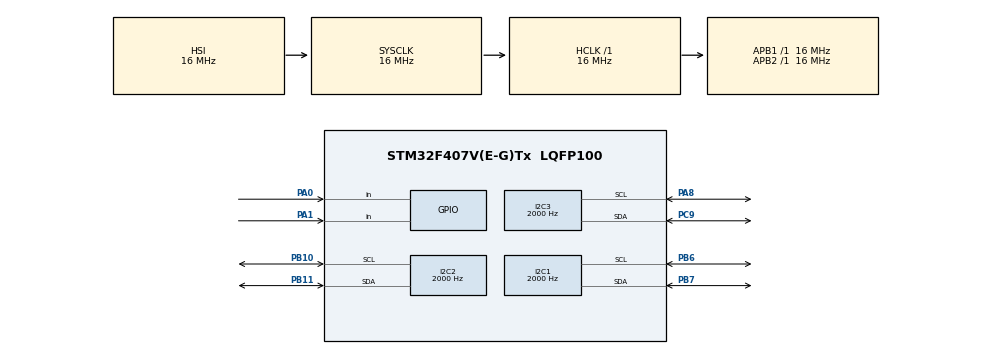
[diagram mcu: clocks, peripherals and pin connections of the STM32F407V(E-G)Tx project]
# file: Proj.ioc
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I2C1.ClockSpeed=2000
I2C1.OwnAddress=51
I2C2.ClockSpeed=2000
I2C2.OwnAddress=52
I2C3.ClockSpeed=2000
I2C3.OwnAddress=53
Mcu.Family=STM32F4
Mcu.Name=STM32F407V(E-G)Tx
Mcu.Package=LQFP100
NVIC.I2C1_ER_IRQn=true\:0\:0\:false\:false\:true\:true\:true
NVIC.I2C1_EV_IRQn=true\:0\:0\:false\:false\:true\:true\:true
NVIC.PriorityGroup=NVIC_PRIORITYGROUP_4
PA0-WKUP.Signal=GPIO_Input
PA1.Signal=GPIO_Input
PA8.Mode=I2C
PA8.Signal=I2C3_SCL
PB10.Mode=I2C
PB10.Signal=I2C2_SCL
PB11.Mode=I2C
PB11.Signal=I2C2_SDA
PB6.Mode=I2C
PB6.Signal=I2C1_SCL
PB7.Mode=I2C
PB7.Signal=I2C1_SDA
PC9.Mode=I2C
PC9.Signal=I2C3_SDA
ProjectManager.HeapSize=0x200
ProjectManager.StackSize=0x400
ProjectManager.TargetToolchain=TrueSTUDIO
RCC.AHBFreq_Value=16000000
RCC.APB1Freq_Value=16000000
RCC.APB2Freq_Value=16000000
RCC.CortexFreq_Value=16000000
RCC.HSE_VALUE=25000000
RCC.HSI_VALUE=16000000
RCC.LSE_VALUE=32768
RCC.SYSCLKFreq_VALUE=16000000
RCC.VCOOutputFreq_Value=192000000
board=custom

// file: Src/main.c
/* USER CODE BEGIN Header */
/**
  ******************************************************************************
  * @file           : main.c
  * @brief          : Main program body
  ******************************************************************************
  * @attention
  *
  * <h2><center>&copy; Copyright (c) 2020 STMicroelectronics.
  * All rights reserved.</center></h2>
  *
  * This software component is licensed by ST under BSD 3-Clause license,
  * the "License"; You may not use this file except in compliance with the
  * License. You may obtain a copy of the License at:
  *                        opensource.org/licenses/BSD-3-Clause
  *
  ******************************************************************************
  */
/* USER CODE END Header */

#include "main.h"

/* USER CODE BEGIN Includes */
#include "I2CTests.h"
/* USER CODE END Includes */

void SystemClock_Config(void);
static void MX_GPIO_Init(void);
static void MX_I2C1_Init(void);
static void MX_I2C2_Init(void);
static void MX_I2C3_Init(void);

int main(void)
{

  /* MCU Configuration--------------------------------------------------------*/

  /* Reset of all peripherals, Initializes the Flash interface and the Systick. */
  HAL_Init();

  /* Configure the system clock */
  SystemClock_Config();

  /* Initialize all configured peripherals */
  MX_GPIO_Init();
  MX_I2C1_Init();
  MX_I2C2_Init();
  MX_I2C3_Init();

  /* Infinite loop */
  /* USER CODE BEGIN WHILE */
  uint8_t aTxBuffer[8] = {0x22, 0x22, 0x22};////�����, ���, ����
//  uint8_t adrDev = 0xD0;
  while (1)
  {
//	if(HAL_GPIO_ReadPin(GPIOA,GPIO_PIN_0) == GPIO_PIN_SET)
//	{
//		if(HAL_I2C_Slave_Receive(&hi2c1, aTxBuffer, (uint16_t)2, (uint32_t)2000) == HAL_OK)
//		{
//			asm("nop");
//		}
//	}
//
//	uint8_t res = HAL_GPIO_ReadPin(GPIOA,GPIO_PIN_1);
//	if(res == GPIO_PIN_SET)
//	{
//		HAL_I2C_DeInit(&hi2c1);
//		HAL_I2C_Init(&hi2c1);
//	}
//	while(HAL_I2C_Slave_Receive(&hi2c1, aTxBuffer, (uint16_t)1, (uint32_t)100) != HAL_OK);
    /* USER CODE END WHILE */

  }
}

void SystemClock_Config(void)
{
  RCC_OscInitTypeDef RCC_OscInitStruct = {0};
  RCC_ClkInitTypeDef RCC_ClkInitStruct = {0};

  /** Configure the main internal regulator output voltage
  */
  __HAL_RCC_PWR_CLK_ENABLE();
  __HAL_PWR_VOLTAGESCALING_CONFIG(PWR_REGULATOR_VOLTAGE_SCALE1);
  /** Initializes the CPU, AHB and APB busses clocks
  */
  RCC_OscInitStruct.OscillatorType = RCC_OSCILLATORTYPE_HSI;
  RCC_OscInitStruct.HSIState = RCC_HSI_ON;
  RCC_OscInitStruct.HSICalibrationValue = RCC_HSICALIBRATION_DEFAULT;
  RCC_OscInitStruct.PLL.PLLState = RCC_PLL_NONE;
  if (HAL_RCC_OscConfig(&RCC_OscInitStruct) != HAL_OK)
  {
    Error_Handler();
  }
  /** Initializes the CPU, AHB and APB busses clocks
  */
  RCC_ClkInitStruct.ClockType = RCC_CLOCKTYPE_HCLK|RCC_CLOCKTYPE_SYSCLK
                              |RCC_CLOCKTYPE_PCLK1|RCC_CLOCKTYPE_PCLK2;
  RCC_ClkInitStruct.SYSCLKSource = RCC_SYSCLKSOURCE_HSI;
  RCC_ClkInitStruct.AHBCLKDivider = RCC_SYSCLK_DIV1;
  RCC_ClkInitStruct.APB1CLKDivider = RCC_HCLK_DIV1;
  RCC_ClkInitStruct.APB2CLKDivider = RCC_HCLK_DIV1;

  if (HAL_RCC_ClockConfig(&RCC_ClkInitStruct, FLASH_LATENCY_0) != HAL_OK)
  {
    Error_Handler();
  }
}

static void MX_I2C1_Init(void)
{

  LL_I2C_InitTypeDef I2C_InitStruct = {0};

  LL_GPIO_InitTypeDef GPIO_InitStruct = {0};

  LL_AHB1_GRP1_EnableClock(LL_AHB1_GRP1_PERIPH_GPIOB);
  /**I2C1 GPIO Configuration
  PB6   ------> I2C1_SCL
  PB7   ------> I2C1_SDA
  */
  GPIO_InitStruct.Pin = LL_GPIO_PIN_6|LL_GPIO_PIN_7;
  GPIO_InitStruct.Mode = LL_GPIO_MODE_ALTERNATE;
  GPIO_InitStruct.Speed = LL_GPIO_SPEED_FREQ_VERY_HIGH;
  GPIO_InitStruct.OutputType = LL_GPIO_OUTPUT_OPENDRAIN;
  GPIO_InitStruct.Pull = LL_GPIO_PULL_UP;
  GPIO_InitStruct.Alternate = LL_GPIO_AF_4;
  LL_GPIO_Init(GPIOB, &GPIO_InitStruct);

  /* Peripheral clock enable */
  LL_APB1_GRP1_EnableClock(LL_APB1_GRP1_PERIPH_I2C1);

  /* I2C1 interrupt Init */
  NVIC_SetPriority(I2C1_EV_IRQn, NVIC_EncodePriority(NVIC_GetPriorityGrouping(),0, 0));
  NVIC_EnableIRQ(I2C1_EV_IRQn);
  NVIC_SetPriority(I2C1_ER_IRQn, NVIC_EncodePriority(NVIC_GetPriorityGrouping(),0, 0));
  NVIC_EnableIRQ(I2C1_ER_IRQn);

  /** I2C Initialization
  */
  LL_I2C_DisableOwnAddress2(I2C1);
  LL_I2C_DisableGeneralCall(I2C1);
  LL_I2C_EnableClockStretching(I2C1);
  I2C_InitStruct.PeripheralMode = LL_I2C_MODE_I2C;
  I2C_InitStruct.ClockSpeed = 2000;
  I2C_InitStruct.DutyCycle = LL_I2C_DUTYCYCLE_2;
  I2C_InitStruct.OwnAddress1 = 102;
  I2C_InitStruct.TypeAcknowledge = LL_I2C_ACK;
  I2C_InitStruct.OwnAddrSize = LL_I2C_OWNADDRESS1_7BIT;
  LL_I2C_Init(I2C1, &I2C_InitStruct);
  LL_I2C_SetOwnAddress2(I2C1, 0);

}

static void MX_I2C2_Init(void)
{

  LL_I2C_InitTypeDef I2C_InitStruct = {0};

  LL_GPIO_InitTypeDef GPIO_InitStruct = {0};

  LL_AHB1_GRP1_EnableClock(LL_AHB1_GRP1_PERIPH_GPIOB);
  /**I2C2 GPIO Configuration
  PB10   ------> I2C2_SCL
  PB11   ------> I2C2_SDA
  */
  GPIO_InitStruct.Pin = LL_GPIO_PIN_10|LL_GPIO_PIN_11;
  GPIO_InitStruct.Mode = LL_GPIO_MODE_ALTERNATE;
  GPIO_InitStruct.Speed = LL_GPIO_SPEED_FREQ_VERY_HIGH;
  GPIO_InitStruct.OutputType = LL_GPIO_OUTPUT_OPENDRAIN;
  GPIO_InitStruct.Pull = LL_GPIO_PULL_UP;
  GPIO_InitStruct.Alternate = LL_GPIO_AF_4;
  LL_GPIO_Init(GPIOB, &GPIO_InitStruct);

  /* Peripheral clock enable */
  LL_APB1_GRP1_EnableClock(LL_APB1_GRP1_PERIPH_I2C2);

  /** I2C Initialization
  */
  LL_I2C_DisableOwnAddress2(I2C2);
  LL_I2C_DisableGeneralCall(I2C2);
  LL_I2C_EnableClockStretching(I2C2);
  I2C_InitStruct.PeripheralMode = LL_I2C_MODE_I2C;
  I2C_InitStruct.ClockSpeed = 2000;
  I2C_InitStruct.DutyCycle = LL_I2C_DUTYCYCLE_2;
  I2C_InitStruct.OwnAddress1 = 104;
  I2C_InitStruct.TypeAcknowledge = LL_I2C_ACK;
  I2C_InitStruct.OwnAddrSize = LL_I2C_OWNADDRESS1_7BIT;
  LL_I2C_Init(I2C2, &I2C_InitStruct);
  LL_I2C_SetOwnAddress2(I2C2, 0);

}

static void MX_I2C3_Init(void)
{

  LL_I2C_InitTypeDef I2C_InitStruct = {0};

  LL_GPIO_InitTypeDef GPIO_InitStruct = {0};

  LL_AHB1_GRP1_EnableClock(LL_AHB1_GRP1_PERIPH_GPIOC);
  LL_AHB1_GRP1_EnableClock(LL_AHB1_GRP1_PERIPH_GPIOA);
  /**I2C3 GPIO Configuration
  PC9   ------> I2C3_SDA
  PA8   ------> I2C3_SCL
  */
  GPIO_InitStruct.Pin = LL_GPIO_PIN_9;
  GPIO_InitStruct.Mode = LL_GPIO_MODE_ALTERNATE;
  GPIO_InitStruct.Speed = LL_GPIO_SPEED_FREQ_VERY_HIGH;
  GPIO_InitStruct.OutputType = LL_GPIO_OUTPUT_OPENDRAIN;
  GPIO_InitStruct.Pull = LL_GPIO_PULL_UP;
  GPIO_InitStruct.Alternate = LL_GPIO_AF_4;
  LL_GPIO_Init(GPIOC, &GPIO_InitStruct);

  GPIO_InitStruct.Pin = LL_GPIO_PIN_8;
  GPIO_InitStruct.Mode = LL_GPIO_MODE_ALTERNATE;
  GPIO_InitStruct.Speed = LL_GPIO_SPEED_FREQ_VERY_HIGH;
  GPIO_InitStruct.OutputType = LL_GPIO_OUTPUT_OPENDRAIN;
  GPIO_InitStruct.Pull = LL_GPIO_PULL_UP;
  GPIO_InitStruct.Alternate = LL_GPIO_AF_4;
  LL_GPIO_Init(GPIOA, &GPIO_InitStruct);

  /* Peripheral clock enable */
  LL_APB1_GRP1_EnableClock(LL_APB1_GRP1_PERIPH_I2C3);

  /** I2C Initialization
  */
  LL_I2C_DisableOwnAddress2(I2C3);
  LL_I2C_DisableGeneralCall(I2C3);
  LL_I2C_EnableClockStretching(I2C3);
  I2C_InitStruct.PeripheralMode = LL_I2C_MODE_I2C;
  I2C_InitStruct.ClockSpeed = 2000;
  I2C_InitStruct.DutyCycle = LL_I2C_DUTYCYCLE_2;
  I2C_InitStruct.OwnAddress1 = 106;
  I2C_InitStruct.TypeAcknowledge = LL_I2C_ACK;
  I2C_InitStruct.OwnAddrSize = LL_I2C_OWNADDRESS1_7BIT;
  LL_I2C_Init(I2C3, &I2C_InitStruct);
  LL_I2C_SetOwnAddress2(I2C3, 0);

}

static void MX_GPIO_Init(void)
{
  GPIO_InitTypeDef GPIO_InitStruct = {0};

  /* GPIO Ports Clock Enable */
  __HAL_RCC_GPIOA_CLK_ENABLE();
  __HAL_RCC_GPIOB_CLK_ENABLE();
  __HAL_RCC_GPIOC_CLK_ENABLE();

  /*Configure GPIO pins : PA0 PA1 */
  GPIO_InitStruct.Pin = GPIO_PIN_0|GPIO_PIN_1;
  GPIO_InitStruct.Mode = GPIO_MODE_INPUT;
  GPIO_InitStruct.Pull = GPIO_NOPULL;
  HAL_GPIO_Init(GPIOA, &GPIO_InitStruct);

}

void Error_Handler(void)
{
}

/************************ (C) COPYRIGHT STMicroelectronics *****END OF FILE****/
